AUTOSAR XML (schema 4-2-2)
package /ComponentTypes
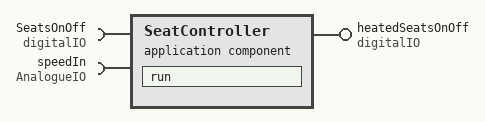
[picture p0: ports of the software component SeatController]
  application sw component type SeatController
    require port SeatsOnOff: nonqueued-receiver-com-spec{data-element=boolean, filter=data-filter-type=ALWAYS, init-value=0}, required-interface=digitalIO
    provide port heatedSeatsOnOff: nonqueued-sender-com-spec=boolean, provided-interface=digitalIO
    require port speedIn: nonqueued-receiver-com-spec{data-element=speed, init-value=0}, required-interface=AnalogueIO
    behavior SeatController_InternalBehavior: data-type-mapping=speedMapSet
      data received event DRT_run_SeatsOnOff_boolean: start-on-event=run, data=SeatsOnOff.boolean
      data received event DRT_run_speedIn_speed: start-on-event=run, data=speedIn.speed
      runnable run
        data-receive-point-by-arguments:
          access REC_SeatsOnOff_boolean: accessed-variable=SeatsOnOff.boolean
          access REC_speedIn_speed: accessed-variable=speedIn.speed
        data-send-points:
          access SEND_heatedSeatsOnOff_boolean: accessed-variable=heatedSeatsOnOff.boolean
  swc implementation SeatController_Implementation: behavior=SeatController_InternalBehavior
